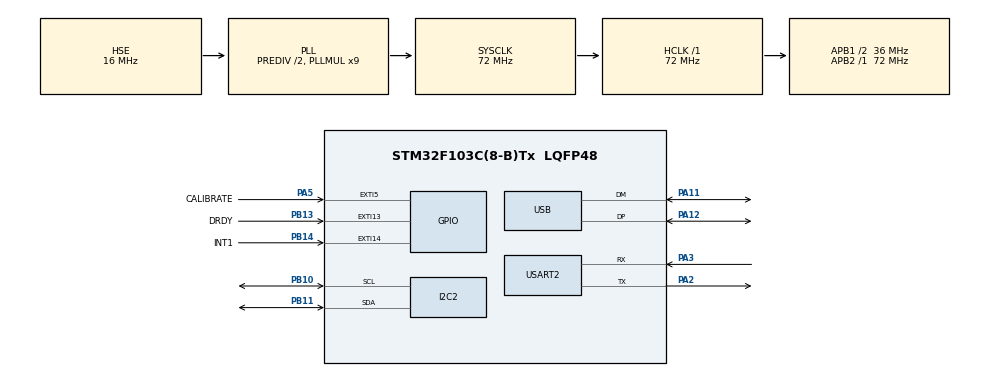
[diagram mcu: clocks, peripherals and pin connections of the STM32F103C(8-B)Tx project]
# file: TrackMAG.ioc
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Dma.Request0=USART2_TX
Dma.USART2_TX.0.Direction=DMA_MEMORY_TO_PERIPH
Dma.USART2_TX.0.Instance=DMA1_Channel7
Dma.USART2_TX.0.MemDataAlignment=DMA_MDATAALIGN_BYTE
Dma.USART2_TX.0.MemInc=DMA_MINC_ENABLE
Dma.USART2_TX.0.Mode=DMA_NORMAL
Dma.USART2_TX.0.PeriphDataAlignment=DMA_PDATAALIGN_BYTE
Dma.USART2_TX.0.PeriphInc=DMA_PINC_DISABLE
Dma.USART2_TX.0.Priority=DMA_PRIORITY_LOW
I2C2.I2C_Mode=I2C_Fast
Mcu.Family=STM32F1
Mcu.Name=STM32F103C(8-B)Tx
Mcu.Package=LQFP48
NVIC.DMA1_Channel7_IRQn=true\:0\:0\:false\:false\:true\:false\:true\:true
NVIC.EXTI15_10_IRQn=true\:0\:0\:false\:false\:true\:true\:true\:true
NVIC.EXTI9_5_IRQn=true\:0\:0\:false\:false\:true\:true\:true\:true
NVIC.PriorityGroup=NVIC_PRIORITYGROUP_4
NVIC.TIM1_UP_IRQn=true\:15\:0\:false\:false\:true\:false\:true\:true
NVIC.TimeBase=TIM1_UP_IRQn
NVIC.TimeBaseIP=TIM1
NVIC.USART2_IRQn=true\:0\:0\:false\:false\:true\:true\:true\:true
NVIC.USB_LP_CAN1_RX0_IRQn=true\:0\:0\:false\:false\:true\:false\:true\:true
PA11.Mode=Device
PA11.Signal=USB_DM
PA12.Mode=Device
PA12.Signal=USB_DP
PA13.Mode=Serial_Wire
PA13.Signal=SYS_JTMS-SWDIO
PA14.Mode=Serial_Wire
PA14.Signal=SYS_JTCK-SWCLK
PA2.Mode=Asynchronous
PA2.Signal=USART2_TX
PA3.Mode=Asynchronous
PA3.Signal=USART2_RX
PA5.GPIO_Label=CALIBRATE
PA5.GPIO_ModeDefaultEXTI=GPIO_MODE_IT_RISING_FALLING
PA5.GPIO_PuPd=GPIO_PULLUP
PA5.Signal=GPXTI5
PB10.Mode=I2C
PB10.Signal=I2C2_SCL
PB11.Mode=I2C
PB11.Signal=I2C2_SDA
PB13.GPIO_Label=DRDY
PB13.GPIO_ModeDefaultEXTI=GPIO_MODE_IT_RISING
PB13.GPIO_PuPd=GPIO_PULLDOWN
PB13.Signal=GPXTI13
PB14.GPIO_Label=INT1
PB14.GPIO_ModeDefaultEXTI=GPIO_MODE_IT_RISING
PB14.Signal=GPXTI14
PD0-OSC_IN.Mode=HSE-External-Oscillator
PD0-OSC_IN.Signal=RCC_OSC_IN
PD1-OSC_OUT.Mode=HSE-External-Oscillator
PD1-OSC_OUT.Signal=RCC_OSC_OUT
ProjectManager.HeapSize=0x200
ProjectManager.StackSize=0x400
ProjectManager.TargetToolchain=STM32CubeIDE
RCC.AHBFreq_Value=72000000
RCC.APB1CLKDivider=RCC_HCLK_DIV2
RCC.APB1Freq_Value=36000000
RCC.APB1TimFreq_Value=72000000
RCC.APB2Freq_Value=72000000
RCC.APB2TimFreq_Value=72000000
RCC.HCLKFreq_Value=72000000
RCC.HSEDivPLL=RCC_HSE_PREDIV_DIV2
RCC.HSE_VALUE=16000000
RCC.PLLMUL=RCC_PLL_MUL9
RCC.SYSCLKFreq_VALUE=72000000
RCC.SYSCLKSource=RCC_SYSCLKSOURCE_PLLCLK
RCC.USBFreq_Value=48000000
RCC.USBPrescaler=RCC_USBCLKSOURCE_PLL_DIV1_5
STMicroelectronics.X-CUBE-MEMS1.10.0.0.SensorsJjSTM32IiMotionFXIiLibraryJjCore=true
USART2.VirtualMode=VM_ASYNC
USB_DEVICE.CLASS_NAME_FS=CUSTOM_HID
USB_DEVICE.MANUFACTURER_STRING=mupf.dev
USB_DEVICE.PRODUCT_STRING_CUSTOMHID_FS=TrackMAG v1
USB_DEVICE.USBD_CUSTOMHID_OUTREPORT_BUF_SIZE=64
USB_DEVICE.USBD_CUSTOM_HID_REPORT_DESC_SIZE=22
USB_DEVICE.VirtualMode=CustomHid
USB_DEVICE.VirtualModeFS=Custom_Hid_FS
VP_CRC_VS_CRC.Mode=CRC_Activate
VP_STMicroelectronics.X-CUBE-MEMS1_VS_SensorsJjSTM32IiMotionFXIiLibrary_2.8.0_10.0.0.Mode=SensorsJjSTM32IiMotionFXIiLibrary
VP_SYS_VS_tim1.Mode=TIM1
VP_USB_DEVICE_VS_USB_DEVICE_CUSTOM_HID_FS.Mode=CUSTOM_HID_FS
board=custom

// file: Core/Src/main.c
/* USER CODE BEGIN Header */
/**
  ******************************************************************************
  * @file           : main.c
  * @brief          : Main program body
  ******************************************************************************
  * @attention
  *
  * Copyright (c) 2023 STMicroelectronics.
  * All rights reserved.
  *
  * This software is licensed under terms that can be found in the LICENSE file
  * in the root directory of this software component.
  * If no LICENSE file comes with this software, it is provided AS-IS.
  *
  ******************************************************************************
  */
/* USER CODE END Header */
#include "main.h"
#include "crc.h"
#include "dma.h"
#include "i2c.h"
#include "usart.h"
#include "usb_device.h"
#include "gpio.h"

/* USER CODE BEGIN Includes */
#include "app_trackmag.h"
/* USER CODE END Includes */

void SystemClock_Config(void);

int main(void)
{
  /* USER CODE BEGIN 1 */
  app_state_t state = APP_INIT;
  /* USER CODE END 1 */

  /* MCU Configuration--------------------------------------------------------*/

  /* Reset of all peripherals, Initializes the Flash interface and the Systick. */
  HAL_Init();

  /* Configure the system clock */
  SystemClock_Config();

  /* Initialize all configured peripherals */
  MX_GPIO_Init();
  MX_DMA_Init();
  MX_I2C2_Init();
  MX_USART2_UART_Init();
  MX_USB_DEVICE_Init();
  MX_CRC_Init();

  /* Infinite loop */
  /* USER CODE BEGIN WHILE */
  while (1)
  {
    app_update(&state);
    /* USER CODE END WHILE */

    /* USER CODE BEGIN 3 */

    /* DO NOT add an additional delay here!
     * Sample time is handled by mag_update()
     */
  }
  /* USER CODE END 3 */
}

void SystemClock_Config(void)
{
  RCC_OscInitTypeDef RCC_OscInitStruct = {0};
  RCC_ClkInitTypeDef RCC_ClkInitStruct = {0};
  RCC_PeriphCLKInitTypeDef PeriphClkInit = {0};

  /** Initializes the RCC Oscillators according to the specified parameters
  * in the RCC_OscInitTypeDef structure.
  */
  RCC_OscInitStruct.OscillatorType = RCC_OSCILLATORTYPE_HSE;
  RCC_OscInitStruct.HSEState = RCC_HSE_ON;
  RCC_OscInitStruct.HSEPredivValue = RCC_HSE_PREDIV_DIV2;
  RCC_OscInitStruct.HSIState = RCC_HSI_ON;
  RCC_OscInitStruct.PLL.PLLState = RCC_PLL_ON;
  RCC_OscInitStruct.PLL.PLLSource = RCC_PLLSOURCE_HSE;
  RCC_OscInitStruct.PLL.PLLMUL = RCC_PLL_MUL9;
  if (HAL_RCC_OscConfig(&RCC_OscInitStruct) != HAL_OK)
  {
    Error_Handler();
  }

  /** Initializes the CPU, AHB and APB buses clocks
  */
  RCC_ClkInitStruct.ClockType = RCC_CLOCKTYPE_HCLK|RCC_CLOCKTYPE_SYSCLK
                              |RCC_CLOCKTYPE_PCLK1|RCC_CLOCKTYPE_PCLK2;
  RCC_ClkInitStruct.SYSCLKSource = RCC_SYSCLKSOURCE_PLLCLK;
  RCC_ClkInitStruct.AHBCLKDivider = RCC_SYSCLK_DIV1;
  RCC_ClkInitStruct.APB1CLKDivider = RCC_HCLK_DIV2;
  RCC_ClkInitStruct.APB2CLKDivider = RCC_HCLK_DIV1;

  if (HAL_RCC_ClockConfig(&RCC_ClkInitStruct, FLASH_LATENCY_2) != HAL_OK)
  {
    Error_Handler();
  }
  PeriphClkInit.PeriphClockSelection = RCC_PERIPHCLK_USB;
  PeriphClkInit.UsbClockSelection = RCC_USBCLKSOURCE_PLL_DIV1_5;
  if (HAL_RCCEx_PeriphCLKConfig(&PeriphClkInit) != HAL_OK)
  {
    Error_Handler();
  }
}

void HAL_TIM_PeriodElapsedCallback(TIM_HandleTypeDef *htim)
{
  if (htim->Instance == TIM1) {
    HAL_IncTick();
  }
}

void Error_Handler(void)
{
  __disable_irq();
  while (1)
  {
  }
}
